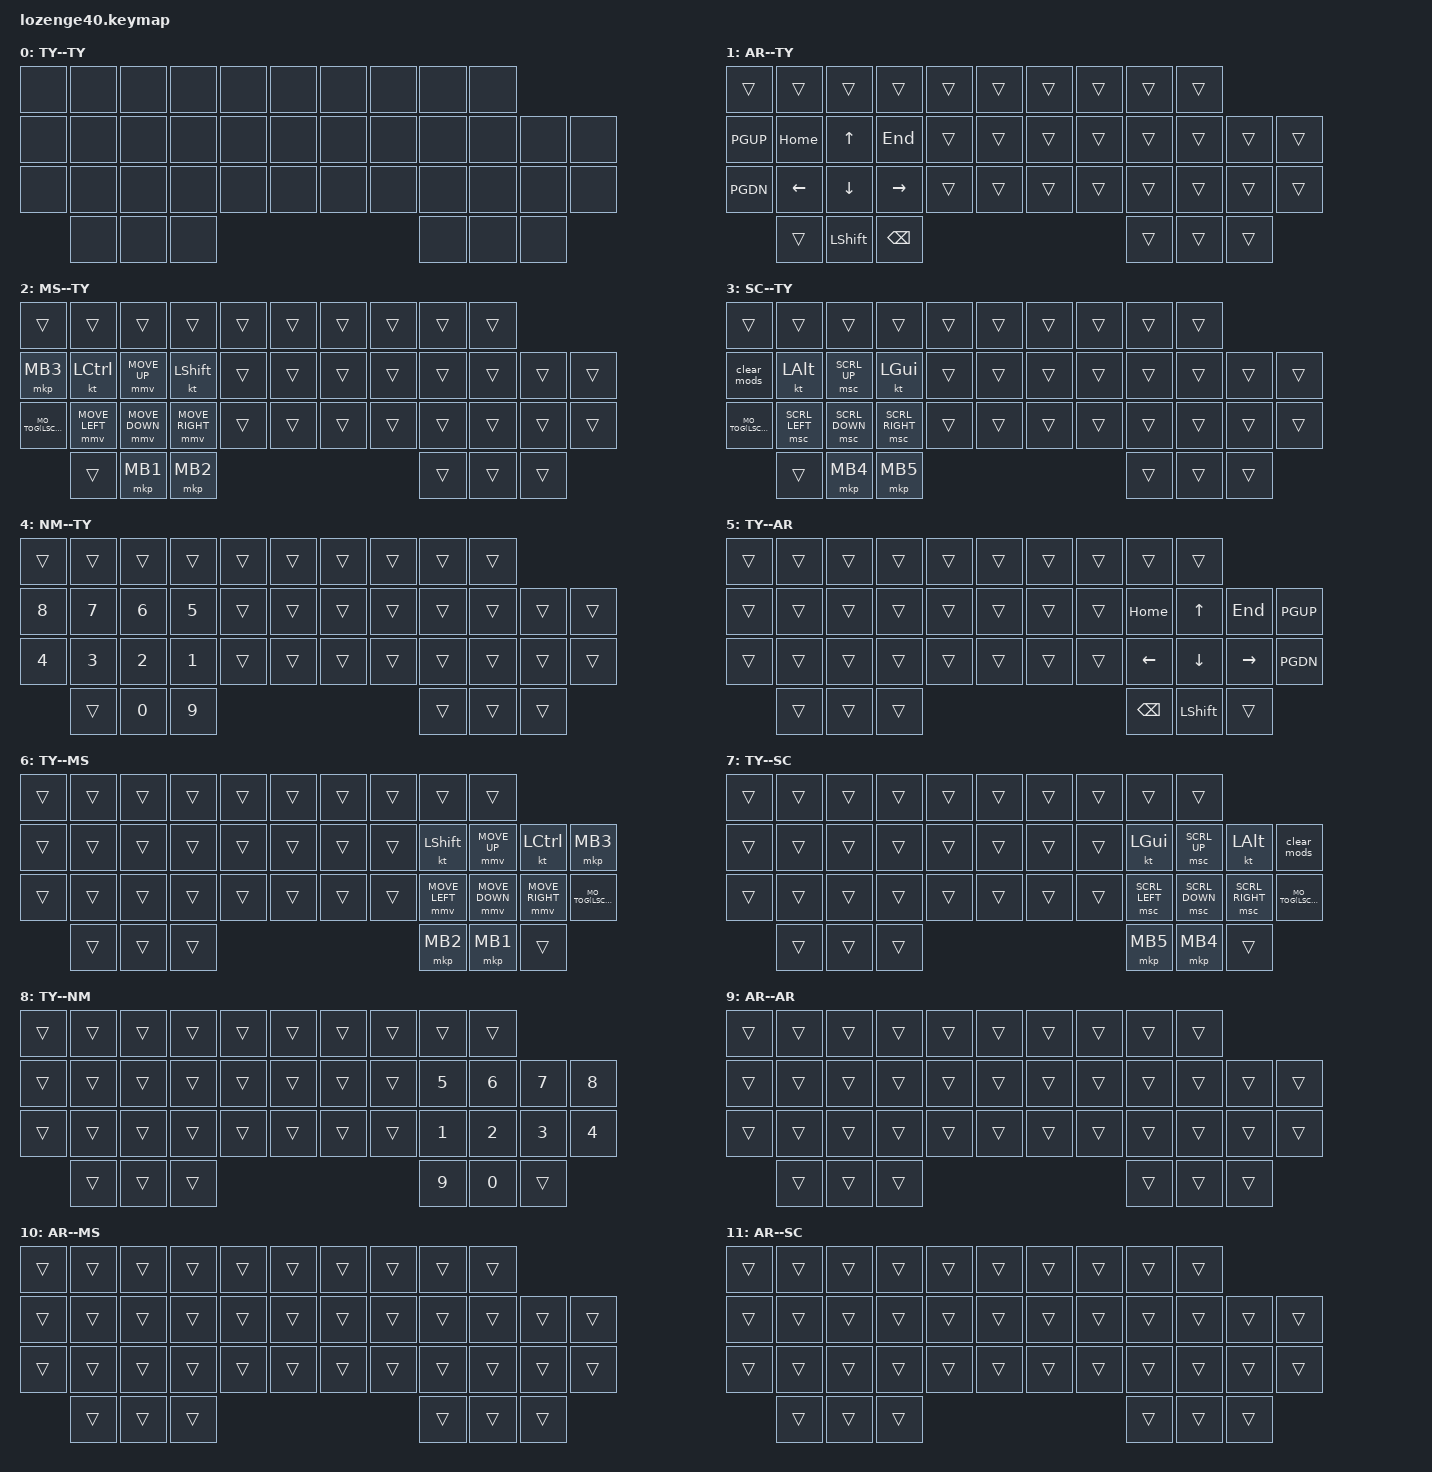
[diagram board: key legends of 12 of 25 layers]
/*
 * Copyright (c) 2020 The ZMK Contributors
 *
 * SPDX-License-Identifier: MIT
 */

#include <behaviors.dtsi>
#include <dt-bindings/zmk/bt.h>
#include <dt-bindings/zmk/keys.h>
#include <dt-bindings/zmk/outputs.h>
#include <dt-bindings/zmk/pointing.h>

// CONFIG
#define COMBO_TIMEOUT 100
#define STICKY_TIMEOUT 2000

#define LTYPTYP 0
#define LARWL 1
#define LMOVL 2
#define LSCRL 3
#define LNUML 4
#define LARWR 5
#define LMOVR 6
#define LSCRR 7
#define LNUMR 8
#define LARWARW 9
#define LARWMOV 10
#define LARWSCR 11
#define LARWNUM 12
#define LMOVARW 13
#define LMOVMOV 14
#define LMOVSCR 15
#define LMOVNUM 16
#define LSCRARW 17
#define LSCRMOV 18
#define LSCRSCR 19
#define LSCRNUM 20
#define LNUMARW 21
#define LNUMMOV 22
#define LNUMSCR 23
#define LNUMNUM 24

#define TYP_LAYERS_LEFT <0 5 6 7 8>
#define TYP_LAYERS_RIGHT <0 1 2 3 4>
#define NUM_LAYERS_LEFT <4 21 22 23 24>
#define NUM_LAYERS_RIGHT <8 12 16 20 24>

// LEFT SIDE (Mapped to Lozenge40 Home Row)
#define TLP 10 // Top Left Pinky
#define TLR 11 // Top Left Ring
#define TLM 12 // Top Left Middle
#define TLI 13 // Top Left Index
#define BLP 22 // Bottom Left Pinky
#define BLR 23 // Bottom Left Ring
#define BLM 24 // Bottom Left Middle
#define BLI 25 // Bottom Left Index

// LEFT THUMBS
#define LOT 35 // Left Outer Thumb
#define LIT 36 // Left Inner Thumb

// RIGHT SIDE (Mapped to Lozenge40 Home Row)
#define TRI 18 // Top Right Index
#define TRM 19 // Top Right Middle
#define TRR 20 // Top Right Ring
#define TRP 21 // Top Right Pinky
#define BRI 30 // Bottom Right Index
#define BRM 31 // Bottom Right Middle
#define BRR 32 // Bottom Right Ring
#define BRP 33 // Bottom Right Pinky

// RIGHT THUMBS
#define RIT 37 // Right Inner Thumb
#define ROT 38 // Right Outer Thumb

#define MO_TOG(layer) &mo_tog layer layer

&sk {
    release-after-ms = <STICKY_TIMEOUT>;
    quick-release;
};

/ {
  combos {
    compatible = "zmk,combos";
    #include "taipo.dtsi"
  };

  macros {
      clear_mods: clear_mods {
          compatible = "zmk,behavior-macro";
          #binding-cells = <0>;
          wait-ms = <0>;
          tap-ms = <0>;
          bindings = <&kt_off LSHIFT &kt_off LCTRL &kt_off LALT &kt_off LGUI>;
      };
      totypl: goto_typ_left_layer {
          compatible = "zmk,behavior-macro";
          #binding-cells = <0>;
          wait-ms = <0>;
          tap-ms = <0>;
          bindings = <&tog_off LARWL &tog_off LMOVL &tog_off LSCRL &tog_off LNUML>;
      };
      toarwl: goto_arw_left_layer {
          compatible = "zmk,behavior-macro";
          #binding-cells = <0>;
          wait-ms = <0>;
          tap-ms = <0>;
          bindings = <&tog_on LARWL &tog_off LMOVL &tog_off LSCRL &tog_off LNUML>;
      };
      tomovl: goto_mov_left_layer {
          compatible = "zmk,behavior-macro";
          #binding-cells = <0>;
          wait-ms = <0>;
          tap-ms = <0>;
          bindings = <&tog_off LARWL &tog_on LMOVL &tog_off LSCRL &tog_off LNUML>;
      };
      tonuml: goto_num_left_layer {
          compatible = "zmk,behavior-macro";
          #binding-cells = <0>;
          wait-ms = <0>;
          tap-ms = <0>;
          bindings = <&tog_off LARWL &tog_off LMOVL &tog_off LSCRL &tog_on LNUML>;
      };
      totypr: goto_typ_right_layer {
          compatible = "zmk,behavior-macro";
          #binding-cells = <0>;
          wait-ms = <0>;
          tap-ms = <0>;
          bindings = <&tog_off LARWR &tog_off LMOVR &tog_off LSCRR &tog_off LNUMR>;
      };
      toarwr: goto_arw_right_layer {
          compatible = "zmk,behavior-macro";
          #binding-cells = <0>;
          wait-ms = <0>;
          tap-ms = <0>;
          bindings = <&tog_on LARWR &tog_off LMOVR &tog_off LSCRR &tog_off LNUMR>;
      };
      tomovr: goto_mov_right_layer {
          compatible = "zmk,behavior-macro";
          #binding-cells = <0>;
          wait-ms = <0>;
          tap-ms = <0>;
          bindings = <&tog_off LARWR &tog_on LMOVR &tog_off LSCRR &tog_off LNUMR>;
      };
      tonumr: goto_num_right_layer {
          compatible = "zmk,behavior-macro";
          #binding-cells = <0>;
          wait-ms = <0>;
          tap-ms = <0>;
          bindings = <&tog_off LARWR &tog_off LMOVR &tog_off LSCRR &tog_on LNUMR>;
      };
  };

  behaviors {
      tog_on: toggle_layer_on_only {
          compatible = "zmk,behavior-toggle-layer";
          #binding-cells = <1>;
          display-name = "Toggle Layer On";
          toggle-mode = "on";
      };
      tog_off: toggle_layer_off_only {
          compatible = "zmk,behavior-toggle-layer";
          #binding-cells = <1>;
          display-name = "Toggle Layer Off";
          toggle-mode = "off";
      };
      kt_on: key_toggle_on_only {
          compatible = "zmk,behavior-key-toggle";
          #binding-cells = <1>;
          display-name = "Key Toggle On";
          toggle-mode = "on";
      };

      kt_off: key_toggle_off_only {
          compatible = "zmk,behavior-key-toggle";
          #binding-cells = <1>;
          display-name = "Key Toggle Off";
          toggle-mode = "off";
      };

      td_shft: td_shft {
          compatible = "zmk,behavior-tap-dance";
          #binding-cells = <0>;
          tapping-term-ms = <200>;
          bindings = <&sk LSHIFT>, <&kt LSHIFT>;
      };
      td_ctrl: td_ctrl {
          compatible = "zmk,behavior-tap-dance";
          #binding-cells = <0>;
          tapping-term-ms = <200>;
          bindings = <&sk LCTRL>, <&kt LCTRL>;
      };
      td_alt: td_alt {
          compatible = "zmk,behavior-tap-dance";
          #binding-cells = <0>;
          tapping-term-ms = <200>;
          bindings = <&sk LALT>, <&kt LALT>;
      };
      td_gui: td_gui {
          compatible = "zmk,behavior-tap-dance";
          #binding-cells = <0>;
          tapping-term-ms = <200>;
          bindings = <&sk LGUI>, <&kt LGUI>;
      };

      mo_tog: behavior_mo_tog {
            compatible = "zmk,behavior-hold-tap";
            #binding-cells = <2>;
            flavor = "hold-preferred";
            tapping-term-ms = <200>;
            bindings = <&mo>, <&tog>;
        };
    };

  keymap {
    compatible = "zmk,keymap";

    typ_typ_layer {
      display-name = "TY--TY";
      bindings = < &none &none &none &none &none &none &none &none &none &none &none &none &none &none &none &none &none &none &none &none &none &none &none &none &none &none &none &none &none &none &none &none &none &none &none &none &none &none &none &none >;
    };

    arwl_layer {
      display-name = "AR--TY";
      bindings = <
        &trans &trans &trans &trans &trans &trans &trans &trans &trans &trans
        &kp PGUP   &kp HOME   &kp UP     &kp END    &trans &trans &trans &trans &trans &trans &trans &trans
        &kp PGDN   &kp LEFT   &kp DOWN   &kp RIGHT  &trans &trans &trans &trans &trans &trans &trans &trans
                   &trans     &kp LSHFT  &kp BSPC                              &trans &trans &trans
      >;
    };
    movl_layer {
      display-name = "MS--TY";
      bindings = <
        &trans &trans &trans &trans &trans &trans &trans &trans &trans &trans
        &mkp MB3       &kt LCTRL       &mmv MOVE_UP    &kt LSHFT        &trans &trans &trans &trans &trans &trans &trans &trans
        MO_TOG(LSCRL)  &mmv MOVE_LEFT  &mmv MOVE_DOWN  &mmv MOVE_RIGHT  &trans &trans &trans &trans &trans &trans &trans &trans
                       &trans          &mkp MB1        &mkp MB2                                     &trans &trans &trans
      >;
    };
    scrl_layer {
      display-name = "SC--TY";
      bindings = <
        &trans &trans &trans &trans &trans &trans &trans &trans &trans &trans
        &clear_mods    &kt LALT        &msc SCRL_UP    &kt LGUI         &trans &trans &trans &trans &trans &trans &trans &trans
        MO_TOG(LSCRL)  &msc SCRL_LEFT  &msc SCRL_DOWN  &msc SCRL_RIGHT  &trans &trans &trans &trans &trans &trans &trans &trans
                       &trans          &mkp MB4        &mkp MB5                                     &trans &trans &trans
      >;
    };
    numl_layer {
      display-name = "NM--TY";
      bindings = <
        &trans &trans &trans &trans &trans &trans &trans &trans &trans &trans
        &kp N8  &kp N7  &kp N6  &kp N5    &trans &trans &trans &trans &trans &trans &trans &trans
        &kp N4  &kp N3  &kp N2  &kp N1    &trans &trans &trans &trans &trans &trans &trans &trans
                &trans  &kp N0  &kp N9                                &trans &trans &trans
      >;
    };
    arwr_layer {
      display-name = "TY--AR";
      bindings = <
        &trans &trans &trans &trans &trans &trans &trans &trans &trans &trans
        &trans &trans &trans &trans &trans &trans &trans &trans    &kp HOME  &kp UP      &kp END    &kp PGUP
        &trans &trans &trans &trans &trans &trans &trans &trans    &kp LEFT  &kp DOWN    &kp RIGHT  &kp PGDN 
               &trans &trans &trans                                &kp BSPC  &kp LSHIFT  &trans
      >;
    };
    movr_layer {
      display-name = "TY--MS";
      bindings = <
        &trans &trans &trans &trans &trans &trans &trans &trans &trans &trans
        &trans &trans &trans &trans &trans &trans &trans &trans    &kt LSHFT       &mmv MOVE_UP    &kt LCTRL        &mkp MB3
        &trans &trans &trans &trans &trans &trans &trans &trans    &mmv MOVE_LEFT  &mmv MOVE_DOWN  &mmv MOVE_RIGHT  MO_TOG(LSCRR)
               &trans &trans &trans                                &mkp MB2        &mkp MB1        &trans
      >;
    };
    scrr_layer {
      display-name = "TY--SC";
      bindings = <
        &trans &trans &trans &trans &trans &trans &trans &trans &trans &trans
        &trans &trans &trans &trans &trans &trans &trans &trans    &kt LGUI        &msc SCRL_UP    &kt LALT         &clear_mods
        &trans &trans &trans &trans &trans &trans &trans &trans    &msc SCRL_LEFT  &msc SCRL_DOWN  &msc SCRL_RIGHT  MO_TOG(LSCRR)
               &trans &trans &trans                                &mkp MB5        &mkp MB4        &trans
      >;
    };
    numr_layer {
      display-name = "TY--NM";
      bindings = <
        &trans &trans &trans &trans &trans &trans &trans &trans &trans &trans
        &trans &trans &trans &trans &trans &trans &trans &trans    &kp N5  &kp N6  &kp N7  &kp N8
        &trans &trans &trans &trans &trans &trans &trans &trans    &kp N1  &kp N2  &kp N3  &kp N4 
               &trans &trans &trans                                &kp N9  &kp N0  &trans
      >;
    };

    arw_arw_layer {
      display-name = "AR--AR";
      bindings = < &trans &trans &trans &trans &trans &trans &trans &trans &trans &trans &trans &trans &trans &trans &trans &trans &trans &trans &trans &trans &trans &trans &trans &trans &trans &trans &trans &trans &trans &trans &trans &trans &trans &trans &trans &trans &trans &trans &trans &trans >;
    };
    arw_mov_layer {
      display-name = "AR--MS";
      bindings = < &trans &trans &trans &trans &trans &trans &trans &trans &trans &trans &trans &trans &trans &trans &trans &trans &trans &trans &trans &trans &trans &trans &trans &trans &trans &trans &trans &trans &trans &trans &trans &trans &trans &trans &trans &trans &trans &trans &trans &trans >;
    };
    arw_scr_layer {
      display-name = "AR--SC";
      bindings = < &trans &trans &trans &trans &trans &trans &trans &trans &trans &trans &trans &trans &trans &trans &trans &trans &trans &trans &trans &trans &trans &trans &trans &trans &trans &trans &trans &trans &trans &trans &trans &trans &trans &trans &trans &trans &trans &trans &trans &trans >;
    };
    arw_num_layer {
      display-name = "AR--NM";
      bindings = < &trans &trans &trans &trans &trans &trans &trans &trans &trans &trans &trans &trans &trans &trans &trans &trans &trans &trans &trans &trans &trans &trans &trans &trans &trans &trans &trans &trans &trans &trans &trans &trans &trans &trans &trans &trans &trans &trans &trans &trans >;
    };
    mov_arw_layer {
      display-name = "MS--AR";
      bindings = < &trans &trans &trans &trans &trans &trans &trans &trans &trans &trans &trans &trans &trans &trans &trans &trans &trans &trans &trans &trans &trans &trans &trans &trans &trans &trans &trans &trans &trans &trans &trans &trans &trans &trans &trans &trans &trans &trans &trans &trans >;
    };
    mov_mov_layer {
      display-name = "MS--MS";
      bindings = < &trans &trans &trans &trans &trans &trans &trans &trans &trans &trans &trans &trans &trans &trans &trans &trans &trans &trans &trans &trans &trans &trans &trans &trans &trans &trans &trans &trans &trans &trans &trans &trans &trans &trans &trans &trans &trans &trans &trans &trans >;
    };
    mov_scr_layer {
      display-name = "MS--SC";
      bindings = < &trans &trans &trans &trans &trans &trans &trans &trans &trans &trans &trans &trans &trans &trans &trans &trans &trans &trans &trans &trans &trans &trans &trans &trans &trans &trans &trans &trans &trans &trans &trans &trans &trans &trans &trans &trans &trans &trans &trans &trans >;
    };
    mov_num_layer {
      display-name = "MS--NM";
      bindings = < &trans &trans &trans &trans &trans &trans &trans &trans &trans &trans &trans &trans &trans &trans &trans &trans &trans &trans &trans &trans &trans &trans &trans &trans &trans &trans &trans &trans &trans &trans &trans &trans &trans &trans &trans &trans &trans &trans &trans &trans >;
    };
    scr_arw_layer {
      display-name = "SC--AR";
      bindings = < &trans &trans &trans &trans &trans &trans &trans &trans &trans &trans &trans &trans &trans &trans &trans &trans &trans &trans &trans &trans &trans &trans &trans &trans &trans &trans &trans &trans &trans &trans &trans &trans &trans &trans &trans &trans &trans &trans &trans &trans >;
    };
    scr_mov_layer {
      display-name = "SC--MS";
      bindings = < &trans &trans &trans &trans &trans &trans &trans &trans &trans &trans &trans &trans &trans &trans &trans &trans &trans &trans &trans &trans &trans &trans &trans &trans &trans &trans &trans &trans &trans &trans &trans &trans &trans &trans &trans &trans &trans &trans &trans &trans >;
    };
    scr_scr_layer {
      display-name = "SC--SC";
      bindings = < &trans &trans &trans &trans &trans &trans &trans &trans &trans &trans &trans &trans &trans &trans &trans &trans &trans &trans &trans &trans &trans &trans &trans &trans &trans &trans &trans &trans &trans &trans &trans &trans &trans &trans &trans &trans &trans &trans &trans &trans >;
    };
    scr_num_layer {
      display-name = "SC--NM";
      bindings = < &trans &trans &trans &trans &trans &trans &trans &trans &trans &trans &trans &trans &trans &trans &trans &trans &trans &trans &trans &trans &trans &trans &trans &trans &trans &trans &trans &trans &trans &trans &trans &trans &trans &trans &trans &trans &trans &trans &trans &trans >;
    };
    num_arw_layer {
      display-name = "NM--AR";
      bindings = < &trans &trans &trans &trans &trans &trans &trans &trans &trans &trans &trans &trans &trans &trans &trans &trans &trans &trans &trans &trans &trans &trans &trans &trans &trans &trans &trans &trans &trans &trans &trans &trans &trans &trans &trans &trans &trans &trans &trans &trans >;
    };
    num_mov_layer {
      display-name = "NM--MS";
      bindings = < &trans &trans &trans &trans &trans &trans &trans &trans &trans &trans &trans &trans &trans &trans &trans &trans &trans &trans &trans &trans &trans &trans &trans &trans &trans &trans &trans &trans &trans &trans &trans &trans &trans &trans &trans &trans &trans &trans &trans &trans >;
    };
    num_scr_layer {
      display-name = "NM--SC";
      bindings = < &trans &trans &trans &trans &trans &trans &trans &trans &trans &trans &trans &trans &trans &trans &trans &trans &trans &trans &trans &trans &trans &trans &trans &trans &trans &trans &trans &trans &trans &trans &trans &trans &trans &trans &trans &trans &trans &trans &trans &trans >;
    };
    num_num_layer {
      display-name = "NM--NM";
      bindings = < &trans &trans &trans &trans &trans &trans &trans &trans &trans &trans &trans &trans &trans &trans &trans &trans &trans &trans &trans &trans &trans &trans &trans &trans &trans &trans &trans &trans &trans &trans &trans &trans &trans &trans &trans &trans &trans &trans &trans &trans >;
    };
  };

  conditional_layers {
        compatible = "zmk,conditional-layers";
        arw_arw_layer_condition {
            if-layers = <LARWL LARWR>;
            then-layer = <LARWARW>;
        };
        arw_mov_layer_condition {
            if-layers = <LARWL LMOVR>;
            then-layer = <LARWMOV>;
        };
        arw_scr_layer_condition {
            if-layers = <LARWL LSCRR>;
            then-layer = <LARWSCR>;
        };
        arw_num_layer_condition {
            if-layers = <LARWL LNUMR>;
            then-layer = <LARWNUM>;
        };
        mov_arw_layer_condition {
            if-layers = <LMOVL LARWR>;
            then-layer = <LMOVARW>;
        };
        mov_mov_layer_condition {
            if-layers = <LMOVL LMOVR>;
            then-layer = <LMOVMOV>;
        };
        mov_scr_layer_condition {
            if-layers = <LMOVL LSCRR>;
            then-layer = <LMOVSCR>;
        };
        mov_num_layer_condition {
            if-layers = <LMOVL LNUMR>;
            then-layer = <LMOVNUM>;
        };
        scr_arw_layer_condition {
            if-layers = <LSCRL LARWR>;
            then-layer = <LSCRARW>;
        };
        scr_mov_layer_condition {
            if-layers = <LSCRL LMOVR>;
            then-layer = <LSCRMOV>;
        };
        scr_scr_layer_condition {
            if-layers = <LSCRL LSCRR>;
            then-layer = <LSCRSCR>;
        };
        scr_num_layer_condition {
            if-layers = <LSCRL LNUMR>;
            then-layer = <LSCRNUM>;
        };
        num_arw_layer_condition {
            if-layers = <LNUML LARWR>;
            then-layer = <LNUMARW>;
        };
        num_mov_layer_condition {
            if-layers = <LNUML LMOVR>;
            then-layer = <LNUMMOV>;
        };
        num_scr_layer_condition {
            if-layers = <LNUML LSCRR>;
            then-layer = <LNUMSCR>;
        };
        num_num_layer_condition {
            if-layers = <LNUML LNUMR>;
            then-layer = <LNUMNUM>;
        };
    };
};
